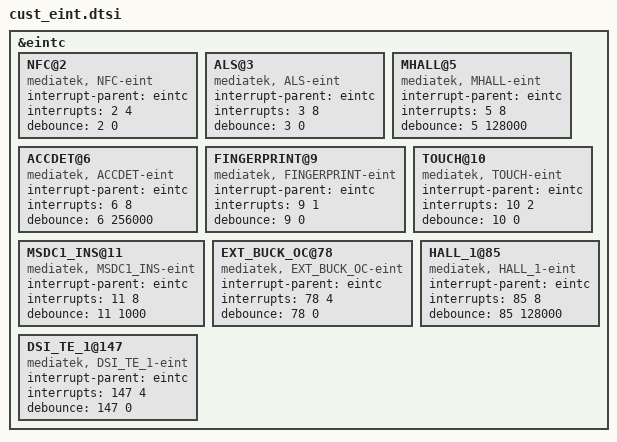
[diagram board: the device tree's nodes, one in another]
/*
 * Generated by MTK SP DrvGen Version 03.13.6 for MT6735M. Copyright MediaTek Inc. (C) 2013.
 * Wed Sep 06 17:12:38 2017
 * Do Not Modify the File.
 */

/*************************
 * EINT DTSI File
*************************/

&eintc {
	NFC@2 {
		compatible = "mediatek, NFC-eint";
		interrupt-parent = <&eintc>;
		interrupts = <2 4>;
		debounce = <2 0>;
	};

	ALS@3 {
		compatible = "mediatek, ALS-eint";
		interrupt-parent = <&eintc>;
		interrupts = <3 8>;
		debounce = <3 0>;
	};

	MHALL@5 {
		compatible = "mediatek, MHALL-eint";
		interrupt-parent = <&eintc>;
		interrupts = <5 8>;
		debounce = <5 128000>;
	};

	ACCDET@6 {
		compatible = "mediatek, ACCDET-eint";
		interrupt-parent = <&eintc>;
		interrupts = <6 8>;
		debounce = <6 256000>;
	};

	FINGERPRINT@9 {
		compatible = "mediatek, FINGERPRINT-eint";
		interrupt-parent = <&eintc>;
		interrupts = <9 1>;
		debounce = <9 0>;
	};

	TOUCH@10 {
		compatible = "mediatek, TOUCH-eint";
		interrupt-parent = <&eintc>;
		interrupts = <10 2>;
		debounce = <10 0>;
	};

	MSDC1_INS@11 {
		compatible = "mediatek, MSDC1_INS-eint";
		interrupt-parent = <&eintc>;
		interrupts = <11 8>;
		debounce = <11 1000>;
	};

	EXT_BUCK_OC@78 {
		compatible = "mediatek, EXT_BUCK_OC-eint";
		interrupt-parent = <&eintc>;
		interrupts = <78 4>;
		debounce = <78 0>;
	};

	HALL_1@85 {
		compatible = "mediatek, HALL_1-eint";
		interrupt-parent = <&eintc>;
		interrupts = <85 8>;
		debounce = <85 128000>;
	};

	DSI_TE_1@147 {
		compatible = "mediatek, DSI_TE_1-eint";
		interrupt-parent = <&eintc>;
		interrupts = <147 4>;
		debounce = <147 0>;
	};

};
